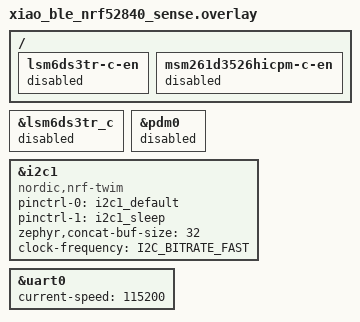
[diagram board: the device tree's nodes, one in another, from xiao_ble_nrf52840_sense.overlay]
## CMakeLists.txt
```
cmake_minimum_required(VERSION 3.20.0)

find_package(Zephyr REQUIRED HINTS $ENV{ZEPHYR_BASE})
project(IMU_vMB01_E)

# NORDIC SDK APP START
target_sources(app PRIVATE
  src/main.c
  src/my_imu_ble_service.c
  src/bno055_driver.c
)

# NORDIC SDK APP END
zephyr_library_include_directories(.)
```

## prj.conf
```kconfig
# --- Logging ---
CONFIG_LOG=y
CONFIG_BT_LOG_LEVEL_ERR=y
CONFIG_LOG_MODE_IMMEDIATE=y
CONFIG_LOG_BACKEND_UART=y

# --- Kernel y Stacks ---
# Tamaños generosos para empezar
CONFIG_BT_RX_STACK_SIZE=2048
CONFIG_MAIN_STACK_SIZE=4096
CONFIG_SYSTEM_WORKQUEUE_STACK_SIZE=2048
CONFIG_ISR_STACK_SIZE=2048

# --- Drivers ---
CONFIG_GPIO=y
CONFIG_I2C=y
CONFIG_FPU=y

# --- Bluetooth ---
CONFIG_BT=y
CONFIG_BT_PERIPHERAL=y
CONFIG_BT_DEVICE_NAME="IMU_OK"

# Configuración de conexión
CONFIG_BT_GATT_CLIENT=y
CONFIG_BT_GAP_AUTO_UPDATE_CONN_PARAMS=n
CONFIG_DESIRED_MIN_CONN_INTERVAL=6
CONFIG_DESIRED_MAX_CONN_INTERVAL=6
CONFIG_BT_PERIPHERAL_PREF_LATENCY=0
CONFIG_BT_PERIPHERAL_PREF_TIMEOUT=400

# Buffers y MTU
CONFIG_BT_USER_DATA_LEN_UPDATE=n
CONFIG_BT_USER_PHY_UPDATE=n
# CONFIG_BT_CTLR_DATA_LENGTH_MAX=251
# CONFIG_BT_BUF_ACL_RX_SIZE=251
# CONFIG_BT_BUF_ACL_TX_SIZE=251
# CONFIG_BT_L2CAP_TX_MTU=247
# Stack para el hilo de recepción de BT
# CONFIG_BT_RX_STACK_SIZE=2048

CONFIG_BT_CTLR_SDC_MAX_CONN_EVENT_LEN_DEFAULT=500
```

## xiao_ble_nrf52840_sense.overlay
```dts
/*
 * Overlay para la placa Seeed XIAO BLE Sense
 *
 * 1. Desactiva los sensores integrados (IMU LSM6DS3 y Micrófono PDM).
 * 2. Habilita la interfaz I2C1
 * 3. Establece la velocidad del puerto serie (UART0) a 115200 baud.
 */

#include <zephyr/dt-bindings/pinctrl/nrf-pinctrl.h>

/* Desactiva el nodo del sensor IMU en el bus I2C0 */
&lsm6ds3tr_c {
	status = "disabled";
};

/* Desactiva el periférico PDM del micrófono */
&pdm0 {
	status = "disabled";
};

/* 
 * Desactiva los reguladores que encienden físicamente el IMU y el micrófono.
 * Esto es importante para ahorrar energía.
 * Se referencian por su ruta completa porque no tienen una etiqueta (label).
 */
/ {
	lsm6ds3tr-c-en {
		status = "disabled";
	};

	msm261d3526hicpm-c-en {
		status = "disabled";
	};
};

/* Habilita el periférico I2C1 */
&i2c1 {
	compatible = "nordic,nrf-twim";
	status = "okay";
	pinctrl-0 = <&i2c1_default>;
	pinctrl-1 = <&i2c1_sleep>;
	pinctrl-names = "default", "sleep";
	zephyr,concat-buf-size = <32>;
	clock-frequency = <I2C_BITRATE_FAST>; /* 400 kHz */
};

/* Establece la velocidad del puerto serie a 115200 */
&uart0 {
	current-speed = <115200>;
};
```

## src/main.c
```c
/*
Hecho por MC. Miguel! - 2025
Implementacion de servidor BLE. Lee datos del BNO (I2C) -> Transmite por BLE.
ENVIA UN PAQUETE CON NO.SEC + QUAT + ACC + GYR + QUAT + ACC + GYR

1. Muestreo del Sensor 
   - Temporizador del kernel a 60 Hz. 
   - La lectura se delega a una cola de trabajo (work queue) dedicada.
2. Empaquetado de Datos
   - Agrupa dos muestras consecutivas CUATERNION + ACC + GYR + número de secuencia en un único paquete de datos.
3. Transmisión BLE
   - Anuncia el dispositivo como un periférico BLE conectable.
   - Una vez que un dispositivo central se conecta, los paquetes de datos se envían mediante notificaciones GATT.
   - El inicio y stop del muestreo y envió se controlan de forma remota escribiendo un comando en la característica Exercise Detection.
     - 0xAA = Inicio.
     - 0xFF = Stop.
4. Sincronización y Concurrencia
   - Usa un semáforo para notificar al hilo de envío de BLE cuándo hay un nuevo paquete listo.
   - Mutex para proteger el búfer de datos compartido contra accesos concurrentes.
5. Gestión y Feedback
   - Gestiona los parámetros de la conexión BLE (PHY, longitud de datos, MTU).
   - LED rojo encendido = inicializaciones en proceso
   - LED's parpadeando en verde = Esperando conexión a central
   - LED's parpadeando en azul = Conectado a central
*/

#include <zephyr/kernel.h>
#include <zephyr/logging/log.h>
#include <zephyr/bluetooth/bluetooth.h>
#include <zephyr/bluetooth/gap.h>
#include <zephyr/bluetooth/uuid.h>
#include <zephyr/bluetooth/conn.h>
#include <zephyr/bluetooth/addr.h>
#include <zephyr/bluetooth/gatt.h>
#include <zephyr/drivers/gpio.h>
#include <zephyr/drivers/i2c.h>

// Include the custom IMU BLE service & BNO driver
#include "my_imu_ble_service.h"
#include "bno055_driver.h"

LOG_MODULE_REGISTER(IMU_server, LOG_LEVEL_INF);

//================================================================================
//                                LED configuration
//================================================================================
#define LED0_NODE DT_ALIAS(led0)
#define LED1_NODE DT_ALIAS(led1)
#define LED2_NODE DT_ALIAS(led2)
static const struct gpio_dt_spec red_led = GPIO_DT_SPEC_GET(LED0_NODE, gpios);
static const struct gpio_dt_spec grn_led = GPIO_DT_SPEC_GET(LED1_NODE, gpios);
static const struct gpio_dt_spec blu_led = GPIO_DT_SPEC_GET(LED2_NODE, gpios);

//================================================================================
//                                BLE configuration
//================================================================================
// Flags to know the status "update" of: PHY, Data Length and Connection Parameters
static bool connect = false;				// Dispositivo conectado?
// static int8_t try_connP = 0, triesUp = 5;	// Intentos de negociacion ConnP, Maximo de intentos

#define DEVICE_NAME CONFIG_BT_DEVICE_NAME	// Device Bluetooth name defined in prj.conf
#define DEVICE_NAME_LEN (sizeof(DEVICE_NAME) - 1)
struct bt_conn *my_conn = NULL;

/***** Advertising parameters strcture *****/
// Small advertising interval for fast connection
static const struct bt_le_adv_param *adv_param = BT_LE_ADV_PARAM(
	(BT_LE_ADV_OPT_CONN |			// Connectable advertising
	BT_LE_ADV_OPT_USE_IDENTITY), 	// Use identity address (Static random address)
	BT_GAP_ADV_FAST_INT_MIN_1,		/* Min Advertising Interval = Value x 0.625ms = 30ms */
	BT_GAP_ADV_FAST_INT_MAX_1,		/* Max Advertising Interval = Value x 0.625ms = 60ms */
	NULL); /* Address of peer, Set to NULL for undirected advertising */

// Definition of advertising data
static const struct bt_data ad[] = {
	BT_DATA_BYTES(BT_DATA_FLAGS, (BT_LE_AD_GENERAL |	// General advertising
		BT_LE_AD_NO_BREDR)),							// No compatible with BR/EDR (Bluetooth Classic)
	BT_DATA(BT_DATA_NAME_COMPLETE, DEVICE_NAME, DEVICE_NAME_LEN), // Use complete name
};

// Scan Response -> UUID of LBS Service
static const struct bt_data sd[] = {BT_DATA_BYTES(BT_DATA_UUID128_ALL, BT_UUID_IMUS_VAL),};
// Structure and definition for change parameters of the connection
// static struct bt_gatt_exchange_params exchange_params;	// variable that holds callback for MTU negotiation

// Work item for advertising & connection setup
static struct k_work adv_work;

//================================================================================
//                              SENSOR y MUESTREO
//================================================================================
// Hilo para enviar el paquete por BLE
#define SEND_STACKSIZE		4096 
#define SEND_PRIORITY		8
// Hilo para muestrear y formar el paquete
#define GETSAMPLE_STACKSIZE	4096
#define GETSAMPLE_PRIORITY	7

#define SAMPLING_PERIOD_US 15000 // 66.6Hz
#define START_DELAY_MS 10000	// Delay before starting the sampling

#define I2C_NODE DT_NODELABEL(i2c1)
static const struct device *i2c1_dev = DEVICE_DT_GET(I2C_NODE);
static uint8_t units; // Store the unit configuration of BNO

// Estructura para muestra -> paquete a transmitir
// Total bytes for 2 x (A + G + M + Q) + NoPkt = 56
// Total bytes for 2 x (A + G + Q) + NoPkt =     44
# define PACKET_SIZE 12
static uint8_t last_packet[PACKET_SIZE];	// Unico buffer
static uint32_t packet_counter = 0;
static bool first_sample_taken = false;
static bool start_send = false;

/*** Recursos del Kernel para el manejo del sensor ***/
// 1. Temporizador
static struct k_timer sensor_timer;

// 2. Cola de trabajo dedicada para leer el sensor fuera de la ISR
// static K_KERNEL_STACK_DEFINE(sensor_work_q_stack, GETSAMPLE_STACKSIZE);
static struct k_work_q sensor_work_q;
static struct k_work sensor_work;

// 3. Mailbox
static struct k_mutex packet_mutex;		// Mutex
static struct k_sem ble_data_sem;		// Semaforo

// NUEVAS DECLARACIONES
K_KERNEL_STACK_MEMBER(sensor_work_q_stack, GETSAMPLE_STACKSIZE); // Stack para la work queue
K_KERNEL_STACK_MEMBER(send_thread_stack, SEND_STACKSIZE);       // Stack para el hilo de envío

static struct k_thread send_thread_data; // Estructura de datos del hilo
k_tid_t send_thread_tid;                 // ID del hilo

//================================================================================
//                         FUNCIONES MUESTREO Y ENVIO
//================================================================================
// Función leer sensor y empaquetar datos
static void sensor_work_handler(struct k_work *work)
{
	if (!start_send) {
		return;
	}
	static uint8_t packet_in_progress[PACKET_SIZE];

	// Primera muestra
	// Guardamos el numero de paquete
	memcpy(packet_in_progress, &packet_counter, sizeof(packet_counter));
	// Guardamos datos quat + acc + gyr
	bno055_read_raw_sensor_data(quat, 8, packet_in_progress, 4);
	
	// LÓGICA DEL MAILBOX
	// Bloquear el mutex para acceder de forma segura al mailbox
	k_mutex_lock(&packet_mutex, K_FOREVER);
	// Sobrescribir el mailbox con el paquete más reciente
	memcpy(last_packet, &packet_in_progress, sizeof(packet_in_progress));
	// Desbloquear el mutex
	k_mutex_unlock(&packet_mutex);
	// Señalizar al hilo BLE que hay nuevos datos listos
	k_sem_give(&ble_data_sem);

	// Incremento del numero de paquete
	packet_counter++;

}

// ISR del temporizador: solo envía el trabajo a la cola
static void timer_expiry_function(struct k_timer *timer_id)
{k_work_submit_to_queue(&sensor_work_q, &sensor_work);}

// Thread for sending data periodically
void send_data_thread(void *p1, void *p2, void *p3)
{
	// ARG_UNUSED se usa para decirle al compilador que es intencional
	// que no usemos estos parámetros. Esto evita warnings de "unused variable".
	ARG_UNUSED(p1);
	ARG_UNUSED(p2);
	ARG_UNUSED(p3);

    uint8_t packet_to_send[PACKET_SIZE];

    while (1) {
        // 1. Esperar a la señal del semaforo. El hilo dormirá aquí sin consumir CPU.
        k_sem_take(&ble_data_sem, K_FOREVER);

        // 2. Una vez despierto, copiar el paquete más reciente del mailbox a un búfer local.
        //    Mutex para garantizar la integridad de los datos.
        k_mutex_lock(&packet_mutex, K_FOREVER);
		memcpy(packet_to_send, &last_packet, sizeof(last_packet));
        k_mutex_unlock(&packet_mutex);

        // 3. Si estamos conectados, suscritos y recibimos el comando
		// if (connect && get_imus_sensordata_notify_enabled()) { //  && start_send
        if (get_imus_sensordata_notify_enabled() && start_send) {
            my_imus_sensordata_notify(packet_to_send, sizeof(packet_to_send));
        }
    }
}

//================================================================================
//                                  FUNCIONES BLE
//================================================================================
// Start the advertisign in the work-queue
static void adv_work_handler(struct k_work *work)
{
	int err = bt_le_adv_start(adv_param, ad, ARRAY_SIZE(ad), sd, ARRAY_SIZE(sd));
	if (err) {LOG_ERR("Advertising failed to start (err %d)\n", err);return;}
	LOG_INF("Advertising successfully started");
}

// Function to start advertising sending the work item to the work-queue
static void advertising_start(void){k_work_submit(&adv_work);}

// Update the connection parameters
// static void update_conn_params(struct bt_conn *conn)
// {
// 	LOG_INF("SOLICITUD CI");
//     int err;
// 	struct bt_le_conn_param *conn_param = BT_LE_CONN_PARAM(
// 		CONFIG_DESIRED_MIN_CONN_INTERVAL,	// Min Connection Interval = Value x 1.25ms
// 		CONFIG_DESIRED_MAX_CONN_INTERVAL,	// Min Connection Interval = Value x 1.25ms
// 		CONFIG_BT_PERIPHERAL_PREF_LATENCY,	// Latency (Number of connection intervals the peripheral can skip)
// 		CONFIG_BT_PERIPHERAL_PREF_TIMEOUT	// Time that the central will wait before disconnecting
// 	);
//     err = bt_conn_le_param_update(conn, conn_param);
//     if (err) LOG_ERR("Failed to request connection parameters update (err %d)", err);
// }

// Inform the MTU exchange
// static void exchange_func(struct bt_conn *conn, uint8_t att_err, struct bt_gatt_exchange_params *params)
// {
// 	LOG_INF("MTU exchange %s", att_err == 0 ? "successful" : "failed");
// 	if (!att_err) {
// 		uint16_t payload_mtu = bt_gatt_get_mtu(conn) - 3;   // 3 bytes used for Attribute headers.
// 		LOG_INF("New MTU: %d bytes", payload_mtu);
// 	}
// }

/************************ Connection events callback functions ************************/
// Callback function for announcing the connection or error in the connection
static void on_connected(struct bt_conn *conn, uint8_t err)
{
	if (err) {
		LOG_ERR("Connection failed (err %u)\n", err);
		return;
	}

	connect = true;
	LOG_INF("Connected. Reading intitial parameters...");

	my_conn = bt_conn_ref(conn);
	struct bt_conn_info info;
	err = bt_conn_get_info(conn, &info);
	if (err) {
		LOG_ERR("bt_conn_get_info() returned %d", err);
		return;
	}

	// Connection parameters to the log
	double connection_interval = info.le.interval*1.25;	// in ms
	uint16_t supervision_timeout = info.le.timeout*10;	// in ms
	LOG_INF("- Connection parameters: interval %.2f ms, latency %d intervals, timeout %d ms", 
			connection_interval, info.le.latency, supervision_timeout);
	
	// LOG_INF("**************");
	// update_conn_params(my_conn);

	// INICIAMOS EL MUESTREO
	start_send = true;
	packet_counter = 0;
	k_sem_take(&ble_data_sem, K_NO_WAIT); 
	k_timer_start(&sensor_timer, K_MSEC(START_DELAY_MS), K_USEC(SAMPLING_PERIOD_US));
}

//Callback function for announcing the disconnection
static void on_disconnected(struct bt_conn *conn, uint8_t reason)
{
	LOG_INF("Disconnected (reason %u)\n", reason);
	bt_conn_unref(my_conn);

	// Reset the connected flag
	connect = false; 

	// Detener muestreo en desconexión
	k_timer_stop(&sensor_timer);
	start_send = false;
}

// Callback function for when a connection object is recycled (restart advertising)
static void recycled_cb(void){LOG_INF("Disconnect complete. Restart advertising\n");advertising_start();}

// Callback to inform the connection parameter update
void on_le_param_updated(struct bt_conn *conn, uint16_t interval, uint16_t latency, uint16_t timeout)
{
	double connection_interval = interval*1.25;         // in ms
	uint16_t supervision_timeout = timeout*10;          // in ms
	LOG_INF("Connection parameters updated: interval %.2f ms, latency %d intervals, timeout %d ms", connection_interval, latency, supervision_timeout);
	
	// if (interval > CONFIG_DESIRED_MAX_CONN_INTERVAL && try_connP < triesUp) {
	// 	try_connP++;
	// 	update_conn_params(my_conn);
	// 	LOG_INF("RETRYING connection parameters update (%d/%d)", try_connP, triesUp);
	// }
}

// Callback structure for connections events
struct bt_conn_cb connection_callbacks = {
	.connected				= on_connected,
	.disconnected			= on_disconnected,
	.recycled				= recycled_cb,
	.le_param_updated		= on_le_param_updated,
};

// Callback function for receiving data from the Exercise Detection characteristic
static void app_exercise_detec_cb(const uint8_t *buf, uint16_t len)
{
	LOG_HEXDUMP_INF(buf, len, "Datos recibidos en Exercise Detection Char:");

	if (len == 1) {
		// Iniciar muestreo
		if (buf[0] == 0xAA) {
			start_send = true;
			packet_counter = 0;
			first_sample_taken = false;
			k_sem_take(&ble_data_sem, K_NO_WAIT); 
			k_timer_start(&sensor_timer, K_MSEC(START_DELAY_MS), K_USEC(SAMPLING_PERIOD_US));
		}

		// Detener muestreo
		if (buf[0] == 0xFF) {
			k_timer_stop(&sensor_timer);
			start_send = false;
		}
	}
}

static struct my_imus_cb app_callbacks = {
	.exdetection_write_cb = app_exercise_detec_cb, 	// Exercise detection callback
};

// MAIN FUNCTION ********************************************************************
int main(void)
{
	int err;
	//================================================================================
	//                                  1. LED'S
	//================================================================================
	if (!gpio_is_ready_dt(&red_led) && !gpio_is_ready_dt(&grn_led) && !gpio_is_ready_dt(&blu_led)) {
		LOG_ERR("Error led gpio\n");
		return -1;
	}
	gpio_pin_configure_dt(&red_led, GPIO_OUTPUT_ACTIVE);
	gpio_pin_configure_dt(&grn_led, GPIO_OUTPUT_ACTIVE);
	gpio_pin_configure_dt(&blu_led, GPIO_OUTPUT_ACTIVE);
	gpio_pin_set_dt(&red_led, 1);
	gpio_pin_set_dt(&grn_led, 0);
	gpio_pin_set_dt(&blu_led, 0);

	//================================================================================
	//                                 2. SENSOR
	//================================================================================
	if (!device_is_ready(i2c1_dev)) {
		LOG_ERR("I2C-1 not ready");
		return -1;
	}

	LOG_INF("Starting IMU-Node.");

	if (!bno055_init(i2c1_dev, BNO_OPR_MODE_IMU)) {
		LOG_ERR("BNO055 init failed.");
		gpio_pin_set_dt(&red_led, 1);
		return -1;
	} else {
		LOG_INF("BNO055 init OK.");
		
		// Set the external crystal
		bno055_change_crystal(true);

		// Load calibration offsets - Axyz, Mxyz, Gxyz, AccRad, MagRad
		// int16_t calib_offsets[11] = {0};
		// bno055_calibration_offsets(false, calib_offsets);
		// for (int k=0; k<11 ;k++) LOG_INF("%d-%d", k, calib_offsets[k]);
		
		// Read config values (the units are important)
		uint8_t config_values[5];
		bno055_read_config(config_values, false);
		units = config_values[3];
	}

	//================================================================================
	//                            3. TOMA DE MUESTRAS
	//================================================================================
	// Inicializar Mutex y Semáforo PRIMERO
	k_mutex_init(&packet_mutex);
	k_sem_init(&ble_data_sem, 0, 1);

	// Cola de trabajo dedicada
	k_work_queue_start(&sensor_work_q, sensor_work_q_stack, K_KERNEL_STACK_SIZEOF(sensor_work_q_stack),
		K_PRIO_COOP(GETSAMPLE_PRIORITY), NULL);
	k_work_init(&sensor_work, sensor_work_handler);

	// Inicializar el temporizador
	k_timer_init(&sensor_timer, timer_expiry_function, NULL);
	// LOG_INF("Kernel objects for sampling are initialized.");

	// Hilo de envío BLE (Thread)
	send_thread_tid = k_thread_create(&send_thread_data, send_thread_stack, K_KERNEL_STACK_SIZEOF(send_thread_stack), 
		send_data_thread, NULL, NULL, NULL, SEND_PRIORITY, 0, K_NO_WAIT);

	if (!send_thread_tid) {
		LOG_ERR("Failed to create send_data_thread");
		return -1;
	}
	k_thread_name_set(send_thread_tid, "ble_send_thread");
	// LOG_INF("BLE Send Thread created.");

	//================================================================================
	//                               4. BLUETOOTH
	//================================================================================
	// Eneable the bluetooth stack
	err = bt_enable(NULL);
	if (err) {
		LOG_ERR("Bluetooth init failed (err %d)\n", err);
		return -1;
	}

	// Initialize the IMU service with the application callbacks
	err = my_imus_init(&app_callbacks);
	if (err) {
		LOG_ERR("Fail to init IMU Service (err %d)\n", err);
		return -1;
	}
	// Register the connections events callbacks
	bt_conn_cb_register(&connection_callbacks);
	// Initialization of the work item for advertising
	k_work_init(&adv_work, adv_work_handler);
	// Start advertising using the the work-queue
	advertising_start();
	// LOG_INF("Bluetooth stack started and advertising.");

	// Get the Bluetooth device address
	bt_addr_le_t addr;
	size_t count = 1;
	char addr_str[BT_ADDR_LE_STR_LEN];
	bt_id_get(&addr, &count);
	bt_addr_le_to_str(&addr, addr_str, sizeof(addr_str));
	LOG_INF("BLE Name=%s, Address=%s", CONFIG_BT_DEVICE_NAME, addr_str);
	
	//================================================================================
	//                                LED Blink
	//================================================================================
	gpio_pin_set_dt(&red_led, 0);
	for (;;) {
		k_msleep(2000);
		if (connect) {
			gpio_pin_toggle_dt(&blu_led);
			gpio_pin_set_dt(&grn_led, 0);
		} else {
			gpio_pin_toggle_dt(&grn_led);
			gpio_pin_set_dt(&blu_led, 0);
		}
	}
}
```

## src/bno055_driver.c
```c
/* Hecho por M.C. Miguel - 2025!
   BNO055 library for Zephyr RTOS!
   
   For an unknow reason (and contrary what the datasheet says)
   1. The BNO dont reset on power on, so you need to reset it manually.
   2. The BNO need a "big" delay after reset to star working correctly, I recommend 800ms.
   3. The BNO need a "big" delay after set the external crystal, even if the system clock status is ok ... I recommend 650ms.
   To change configuration the BNO needs to be set to CONFIG MODE first
*/

#include "bno055_driver.h"
#include <zephyr/logging/log.h>
#include <zephyr/drivers/i2c.h>
#include <zephyr/sys/byteorder.h>
#include <string.h>

//==================================================================================================
// CONFIGURACIÓN Y VARIABLES PRIVADAS
//==================================================================================================
LOG_MODULE_REGISTER(BNO, LOG_LEVEL_INF);
// Puntero estático al dispositivo I2C, se inicializa en bno055_init
static const struct device *i2c_dev;
#define BNO_CONFIG_DELAY_MS 25 // Pequeño delay después de cambiar de modo

//==================================================================================================
// IMPLEMENTACIÓN DE FUNCIONES PÚBLICAS
//==================================================================================================

bool bno055_reset(void)
{
    // CONFIG MODE -> PAGE 0 -> RESET -> CONFIG MODE -> SYS_TRIG = 0
    if (!bno055_set_config_mode()) return false;

    if (i2c_reg_write_byte(i2c_dev, BNO_DEFAULT_ADDR, BNO_REG_PAGE_ID, BNO_PAGE_0) != 0) {
        LOG_ERR("Failed to set page ID to 0.");
        return false;
    }
    
    if (i2c_reg_write_byte(i2c_dev, BNO_DEFAULT_ADDR, BNO_REG_SYS_TRIGGER, BNO_SYS_TRIGGER_RST_SYS) != 0) {
        LOG_ERR("Failed to write reset command.");
        return false;
    }
    k_msleep(800);

    if (!bno055_set_config_mode()) return false;

    if (i2c_reg_write_byte(i2c_dev, BNO_DEFAULT_ADDR, BNO_REG_SYS_TRIGGER, 0x00) != 0) {
        LOG_ERR("Failed to write reset command.");
        return false;
    }

    LOG_INF("BNO055 reset successfully.");
    return true;
}

bool bno055_init(const struct device *i2c_dev_node, uint8_t initial_op_mode)
{
    i2c_dev = i2c_dev_node; // Asigna el puntero del dispositivo I2C
    if (!device_is_ready(i2c_dev)) {
        LOG_ERR("I2C device not ready.");
        return false;
    }

    // RETASO PARA QUE INICIALICE EL BNO
    k_msleep(800);
    uint8_t chip_id = 0;
    if (i2c_reg_read_byte(i2c_dev, BNO_DEFAULT_ADDR, BNO_REG_CHIP_ID, &chip_id) != 0) {
        LOG_ERR("Failed to read chip ID. BNO055 not found?");
        return false;
    }

    if (chip_id != 0xA0) {
        LOG_ERR("Invalid chip ID: 0x%02X (expected 0xA0)", chip_id);
        return false;
    }
    LOG_INF("BNO055 found with chip ID 0x%02X", chip_id);

    // RESET PARA ELIMINAR CUALQUIER CONFIGURACIÓN ANTERIOR
    if (!bno055_reset()) {
        LOG_ERR("Initial BNO055 reset failed.");
        return false;
    }

    // Configurar el modo de operación
    if (!bno055_change_opm(initial_op_mode)) {
        LOG_ERR("Failed to set initial operation mode.");
        return false;
    }
    
    LOG_INF("BNO055 initialized successfully in mode 0x%02X", initial_op_mode);
    return true;
}

bool bno055_read_config(uint8_t *config_values, bool print_v)
{
    uint8_t page_id, pwr_mode, opr_mode, unit_sel, sys_trigger;
    
    if (i2c_reg_read_byte(i2c_dev, BNO_DEFAULT_ADDR, BNO_REG_PAGE_ID, &page_id) != 0 ||
        i2c_reg_read_byte(i2c_dev, BNO_DEFAULT_ADDR, BNO_REG_PWR_MODE, &pwr_mode) != 0 ||
        i2c_reg_read_byte(i2c_dev, BNO_DEFAULT_ADDR, BNO_REG_OPR_MODE, &opr_mode) != 0 ||
        i2c_reg_read_byte(i2c_dev, BNO_DEFAULT_ADDR, BNO_REG_UNIT_SEL, &unit_sel) != 0 ||
        i2c_reg_read_byte(i2c_dev, BNO_DEFAULT_ADDR, BNO_REG_SYS_TRIGGER, &sys_trigger) != 0) {
        LOG_ERR("Failed to read one or more configuration registers.");
        return false;
    }

    config_values[0] = page_id;
    config_values[1] = pwr_mode;
    config_values[2] = opr_mode;
    config_values[3] = unit_sel;
    config_values[4] = sys_trigger;
    
    if (print_v) printk("BNO Config: PageID=0x%02X, PwrMode=0x%02X, OprMode=0x%02X, Units=0x%02X, Trigger=0x%02X\n", page_id, pwr_mode, opr_mode, unit_sel, sys_trigger);
    return true;
}

bool bno055_calibration_status(uint8_t *cal_values)
{
    uint8_t cal_stat;
    if (i2c_reg_read_byte(i2c_dev, BNO_DEFAULT_ADDR, BNO_REG_CALIB_STAT, &cal_stat) != 0) {
        LOG_ERR("Failed to read calibration status.");
        return false;
    }
    
    cal_values[0] = (cal_stat >> 6) & 0x03; // SYS
    cal_values[1] = (cal_stat >> 4) & 0x03; // ACC
    cal_values[2] = (cal_stat >> 2) & 0x03; // GYR
    cal_values[3] = cal_stat & 0x03;        // MAG
    // cal_values[4] = cal_values[1] + cal_values[2] + cal_values[3] + cal_values[4];
    
    LOG_INF("Calibration status: SYS=%d, ACC=%d, GYR=%d, MAG=%d",
            cal_values[0], cal_values[1], cal_values[2], cal_values[3]);
    return true;
}

bool bno055_set_config_mode(void)
{
    uint8_t current_op_mode;
    if (i2c_reg_read_byte(i2c_dev, BNO_DEFAULT_ADDR, BNO_REG_OPR_MODE, &current_op_mode) != 0) {
        LOG_WRN("Could not read OPR_MODE to check if already in config mode.");
    }

    if (current_op_mode == BNO_OPR_MODE_CONFIG) {
        return true; // Ya está en modo config
    }

    if (i2c_reg_write_byte(i2c_dev, BNO_DEFAULT_ADDR, BNO_REG_OPR_MODE, BNO_OPR_MODE_CONFIG) != 0) {
        LOG_ERR("Failed to set config mode.");
        return false;
    }
    k_msleep(BNO_CONFIG_DELAY_MS);
    return true;
}

bool bno055_change_opm(uint8_t new_op_mode)
{
    if (!bno055_set_config_mode()) return false;

    if (i2c_reg_write_byte(i2c_dev, BNO_DEFAULT_ADDR, BNO_REG_OPR_MODE, new_op_mode) != 0) {
        LOG_ERR("Failed to set new operation mode 0x%02X", new_op_mode);
        return false;
    }
    k_msleep(BNO_CONFIG_DELAY_MS);
    return true;
}

bool bno055_calibration_offsets(bool write, int16_t *offsets)
{
    // The BNO has to be in CONFIG MODE to write or read the calibration offsets
    uint8_t current_mode;
    if (i2c_reg_read_byte(i2c_dev, BNO_DEFAULT_ADDR, BNO_REG_OPR_MODE, &current_mode) != 0) {
        LOG_WRN("Failed to read original op mode.");
        return false;
    }

    if (!bno055_set_config_mode()) return false;

    bool success = false;
    uint8_t buffer[22];
    // WRITE OFFSETS ***************************************************************************
    if (write) {
        for (int i = 0; i < 11; i++) {
            buffer[i * 2] = offsets[i] & 0xFF;
            buffer[i * 2 + 1] = (offsets[i] >> 8) & 0xFF;
        }
        
        success = true;
        if (i2c_burst_write(i2c_dev, BNO_DEFAULT_ADDR, BNO_REG_ACC_OFFSET_X_LSB, buffer, 22) != 0) success = false;
        k_msleep(50);
        // if (i2c_burst_write(i2c_dev, BNO_DEFAULT_ADDR, BNO_REG_ACC_OFFSET_X_LSB, &buffer[6], 6) != 0) success = false;
        // k_msleep(50);
        // if (i2c_burst_write(i2c_dev, BNO_DEFAULT_ADDR, BNO_REG_ACC_OFFSET_X_LSB, &buffer[12], 6) != 0) success = false;
        // k_msleep(50);
        // if (i2c_burst_write(i2c_dev, BNO_DEFAULT_ADDR, BNO_REG_ACC_OFFSET_X_LSB, &buffer[18], 2) != 0) success = false;
        // k_msleep(50);
        // if (i2c_burst_write(i2c_dev, BNO_DEFAULT_ADDR, BNO_REG_ACC_OFFSET_X_LSB, &buffer[20], 2) != 0) success = false;
        // k_msleep(50);

        if (success) LOG_INF("Calibration offsets load OK.");
        else LOG_ERR("Calibration offsets load FAILED.");

    } else { 
    
        // READ OFFSETS **************************************************************************
        if (i2c_burst_read(i2c_dev, BNO_DEFAULT_ADDR, BNO_REG_ACC_OFFSET_X_LSB, buffer, 22) == 0) {
            for (int i = 0; i < 11; i++) {
                offsets[i] = (int16_t)(((uint16_t)buffer[i * 2 + 1] << 8) | (uint16_t)buffer[i * 2]);
            }
            LOG_INF("Calibration offsets read successfully.");
            success = true;
        } else LOG_ERR("Failed to read calibration offsets.");
    }

    // Restaurar el modo de operación original
    if (current_mode != BNO_OPR_MODE_CONFIG) bno055_change_opm(current_mode);
    return success;
}

bool bno055_change_crystal(bool set_external_crystal)
{
    uint8_t current_trigger, current_opm;
    if (i2c_reg_read_byte(i2c_dev, BNO_DEFAULT_ADDR, BNO_REG_SYS_TRIGGER, &current_trigger) != 0) return false;

    bool is_external_now = (current_trigger & BNO_SYS_TRIGGER_EXT_CRYSTAL);
    if (set_external_crystal == is_external_now) {
        LOG_INF("Crystal already in desired state.");
        return true;
    }
    
    // Read the current opm -> set to config mode
    if (i2c_reg_read_byte(i2c_dev, BNO_DEFAULT_ADDR, BNO_REG_OPR_MODE, &current_opm) != 0) return false;
    if (!bno055_set_config_mode()) return false;

    // Check if the BNO is ready to change the crystal
    uint8_t clk_ready;
    for (int i = 0; i < 10; i++) {
        i2c_reg_read_byte(i2c_dev, BNO_DEFAULT_ADDR, 0x38, &clk_ready); // 0x38 = system clock status register
        if (clk_ready & 0x01) k_msleep(100);	// bit0=1, BNO not ready to change the crystal
        else break;								// bit0=0, BNO ready to change the crystal
    }

    // CHANGE CRYSTAL SOURCE **************************************************
    uint8_t new_trigger_val = set_external_crystal ? BNO_SYS_TRIGGER_EXT_CRYSTAL : 0x00;
    if (i2c_reg_write_byte(i2c_dev, BNO_DEFAULT_ADDR, BNO_REG_SYS_TRIGGER, new_trigger_val) != 0) {
        LOG_ERR("Failed to write to SYS_TRIGGER register.");
        return false;
    }
    k_msleep(650);  // Delay to allow the BNO to change the crystal

    // Check if the BNO finished the crystal configuration
    for (int i = 0; i < 10; i++) {
        i2c_reg_read_byte(i2c_dev, BNO_DEFAULT_ADDR, 0x38, &clk_ready);
        if (clk_ready & 0x01) k_msleep(100);	// bit0=1, BNO not ready
        else break;								// bit0=0, BNO ready
    }

    // Verificar el estado del cristal después de cambiarlo
    i2c_reg_read_byte(i2c_dev, BNO_DEFAULT_ADDR, BNO_REG_SYS_TRIGGER, &current_trigger);
    if (new_trigger_val != current_trigger) {
        LOG_ERR("Failed to change crystal");
        if (current_opm != BNO_OPR_MODE_CONFIG) bno055_change_opm(current_opm);
        return false;
    }
    
    LOG_INF("Crystal = 0x%02X (%s)", current_trigger, set_external_crystal ? "external" : "internal");
    // Restaurar el modo de operación original
    if (current_opm != BNO_OPR_MODE_CONFIG) bno055_change_opm(current_opm);
    return true;
}

bool bno055_read_raw_sensor_data(uint8_t start_register, uint8_t bytes_to_read, uint8_t *buffer, uint8_t start_index)
{
    if (i2c_burst_read(i2c_dev, BNO_DEFAULT_ADDR, start_register, &buffer[start_index], bytes_to_read) != 0) {
        LOG_WRN("Failed to read %d bytes from register 0x%02X", bytes_to_read, start_register);
        return false;
    }
    return true;
}

bool bno055_convert_to_units(const uint8_t *in_buffer, uint8_t in_buff_index, float *out_buffer, uint8_t out_buff_index, uint8_t sensor_source, uint8_t units)
{
    float div = 1.0f;
    int stop = 3; // 3 ejes (X,Y,Z) por defecto

    switch (sensor_source) {
        case BNO_REG_LIA:
        case BNO_REG_GRV:
        case BNO_REG_ACC:
            if (units & 0x01)   div = 1.0f;     // mg
            else                div = 100.0f;   // m/s^2
            break;
        case BNO_REG_GYR: 
            if (units & 0x02)   div = 900.0f;   // rps
            else                div = 16.0f;    // dps
            break;
        case BNO_REG_MAG: div = 16.0f; break;  // uT
        case BNO_REG_EUL:
            if (units & 0x04)   div = 900.0f;   // rad
            else                div = 16.0f;    // deg
            break;
        case BNO_REG_QUAT:
            div = 16384.0f;
            stop = 4; // W,X,Y,Z
            break;
        case BNO_REG_TEMP:
            div = 1.0f; // 1 LSB = 1 C
            stop = 1;
            break;
        default:
            LOG_WRN("Unknown sensor source for unit conversion: 0x%02X", sensor_source);
            return false;
    }
    
    for (int i = 0; i < stop; i++) {
        int16_t raw_val = (int16_t)sys_get_le16(&in_buffer[in_buff_index + i * 2]);
        out_buffer[out_buff_index + i] = (float)raw_val / div;
    }
    
    return true;
}
```

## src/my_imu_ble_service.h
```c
#ifndef MY_IMU_BLE_SERVICE_H_
#define MY_IMU_BLE_SERVICE_H_

/**@file
 * @defgroup Bluetooth IMU Service API
 * @{
 * @brief API for the IMU Service (IMUS).
 */

#ifdef __cplusplus
extern "C" {
#endif

#include <zephyr/types.h>

/** @brief IMU Service UUID (random 128-bit UUID). */ 
#define BT_UUID_IMUS_VAL BT_UUID_128_ENCODE(0x5cf33500, 0x538c, 0x4dc9, 0xb54b, 0x0b102623558d)

/** @brief SensorData Characteristic UUID. */
#define BT_UUID_IMUS_DATA_VAL BT_UUID_128_ENCODE(0x5cf33501, 0x538c, 0x4dc9, 0xb54b, 0x0b102623558d)

/** @brief ExerciseDetection Characteristic UUID. */
#define BT_UUID_IMUS_EXDETECTION_VAL BT_UUID_128_ENCODE(0x5cf33502, 0x538c, 0x4dc9, 0xb54b, 0x0b102623558d)

#define BT_UUID_IMUS BT_UUID_DECLARE_128(BT_UUID_IMUS_VAL)
#define BT_UUID_IMUS_DATA BT_UUID_DECLARE_128(BT_UUID_IMUS_DATA_VAL)
#define BT_UUID_IMUS_EXDETECTION BT_UUID_DECLARE_128(BT_UUID_IMUS_EXDETECTION_VAL)

/** @brief Callback type for when an time elapsed of an Exercise is received. */
typedef void (*exdetection_write_cb_t)(const uint8_t *buf, uint16_t send_bytes);

/** @brief Callback struct used by the IMU Service. */
struct my_imus_cb {
	exdetection_write_cb_t exdetection_write_cb; 	// Exercise detection callback
};

/** @brief Initialize IMU Service.
 *
 * This function registers application callback functions with the My IMU
 * Service
 *
 * @param[in] callbacks Struct containing pointers to callback functions
 *			used by the service. This pointer can be NULL
 *			if no callback functions are defined.
 *
 * @retval 0 If the operation was successful.
 *           Otherwise, a (negative) error code is returned.
 */
int my_imus_init(struct my_imus_cb *callbacks);

/** @brief Send the time elapsed of the detected exercise.
 *
 * @param[in] data Pointer of the byte array that contain the time of the detectet exercise.
 * @param[in] len The number of bytes to send.
 * 
 * @retval 0 If the operation was successful. Otherwise, a (negative) error code is returned.
 *
 */
int my_imus_exercisedetection_indicate(const uint8_t *data, uint16_t len);

/** @brief Get the indicate enable status.
 *
 * @retval 0 If the operation was successful. Otherwise, a (negative) error code is returned.
 */
bool get_imus_exercisedetection_indicate_enabled(void);

/** @brief Send the sensor value as notification.
 *
 * This function sends an uint8_t array.
 *
 * @param[in] sensor_data Byte array that contain the sensor data.
 * @param[in] send_bytes The number of bytes to send.
 *
 * @retval 0 If the operation was successful.
 *           Otherwise, a (negative) error code is returned.
 */
int my_imus_sensordata_notify(const uint8_t *sensor_data, uint16_t send_bytes);

/** @brief Get the notification enable status.
 *
 * @retval 0 If the operation was successful. Otherwise, a (negative) error code is returned.
 */
bool get_imus_sensordata_notify_enabled(void);

#ifdef __cplusplus
}
#endif

/**
 * @}
 */

#endif /* MY_IMU_BLE_SERVICE_H_ */
```
